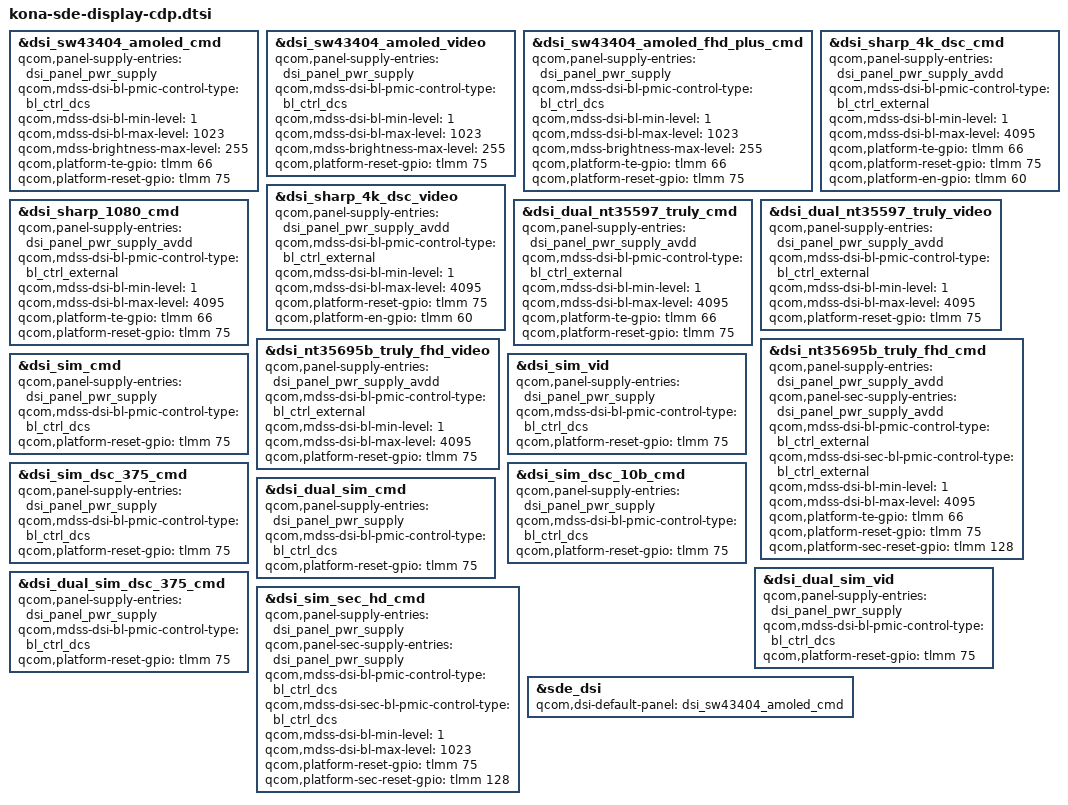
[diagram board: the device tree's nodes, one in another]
#include "kona-sde-display.dtsi"

&dsi_sw43404_amoled_cmd {
	qcom,panel-supply-entries = <&dsi_panel_pwr_supply>;
	qcom,mdss-dsi-bl-pmic-control-type = "bl_ctrl_dcs";
	qcom,mdss-dsi-bl-min-level = <1>;
	qcom,mdss-dsi-bl-max-level = <1023>;
	qcom,mdss-brightness-max-level = <255>;
	qcom,platform-te-gpio = <&tlmm 66 0>;
	qcom,platform-reset-gpio = <&tlmm 75 0>;
};

&dsi_sw43404_amoled_video {
	qcom,panel-supply-entries = <&dsi_panel_pwr_supply>;
	qcom,mdss-dsi-bl-pmic-control-type = "bl_ctrl_dcs";
	qcom,mdss-dsi-bl-min-level = <1>;
	qcom,mdss-dsi-bl-max-level = <1023>;
	qcom,mdss-brightness-max-level = <255>;
	qcom,platform-reset-gpio = <&tlmm 75 0>;
};

&dsi_sw43404_amoled_fhd_plus_cmd {
	qcom,panel-supply-entries = <&dsi_panel_pwr_supply>;
	qcom,mdss-dsi-bl-pmic-control-type = "bl_ctrl_dcs";
	qcom,mdss-dsi-bl-min-level = <1>;
	qcom,mdss-dsi-bl-max-level = <1023>;
	qcom,mdss-brightness-max-level = <255>;
	qcom,platform-te-gpio = <&tlmm 66 0>;
	qcom,platform-reset-gpio = <&tlmm 75 0>;
};

&dsi_sharp_4k_dsc_cmd {
	qcom,panel-supply-entries = <&dsi_panel_pwr_supply_avdd>;
	qcom,mdss-dsi-bl-pmic-control-type = "bl_ctrl_external";
	qcom,mdss-dsi-bl-min-level = <1>;
	qcom,mdss-dsi-bl-max-level = <4095>;
	qcom,platform-te-gpio = <&tlmm 66 0>;
	qcom,platform-reset-gpio = <&tlmm 75 0>;
	qcom,platform-en-gpio = <&tlmm 60 0>;
};

&dsi_sharp_4k_dsc_video {
	qcom,panel-supply-entries = <&dsi_panel_pwr_supply_avdd>;
	qcom,mdss-dsi-bl-pmic-control-type = "bl_ctrl_external";
	qcom,mdss-dsi-bl-min-level = <1>;
	qcom,mdss-dsi-bl-max-level = <4095>;
	qcom,platform-reset-gpio = <&tlmm 75 0>;
	qcom,platform-en-gpio = <&tlmm 60 0>;
};

&dsi_sharp_1080_cmd {
	qcom,panel-supply-entries = <&dsi_panel_pwr_supply_avdd>;
	qcom,mdss-dsi-bl-pmic-control-type = "bl_ctrl_external";
	qcom,mdss-dsi-bl-min-level = <1>;
	qcom,mdss-dsi-bl-max-level = <4095>;
	qcom,platform-te-gpio = <&tlmm 66 0>;
	qcom,platform-reset-gpio = <&tlmm 75 0>;
};

&dsi_dual_nt35597_truly_cmd {
	qcom,panel-supply-entries = <&dsi_panel_pwr_supply_avdd>;
	qcom,mdss-dsi-bl-pmic-control-type = "bl_ctrl_external";
	qcom,mdss-dsi-bl-min-level = <1>;
	qcom,mdss-dsi-bl-max-level = <4095>;
	qcom,platform-te-gpio = <&tlmm 66 0>;
	qcom,platform-reset-gpio = <&tlmm 75 0>;
};

&dsi_dual_nt35597_truly_video {
	qcom,panel-supply-entries = <&dsi_panel_pwr_supply_avdd>;
	qcom,mdss-dsi-bl-pmic-control-type = "bl_ctrl_external";
	qcom,mdss-dsi-bl-min-level = <1>;
	qcom,mdss-dsi-bl-max-level = <4095>;
	qcom,platform-reset-gpio = <&tlmm 75 0>;
};

&dsi_nt35695b_truly_fhd_cmd {
	qcom,panel-supply-entries = <&dsi_panel_pwr_supply_avdd>;
	qcom,panel-sec-supply-entries = <&dsi_panel_pwr_supply_avdd>;
	qcom,mdss-dsi-bl-pmic-control-type = "bl_ctrl_external";
	qcom,mdss-dsi-sec-bl-pmic-control-type = "bl_ctrl_external";
	qcom,mdss-dsi-bl-min-level = <1>;
	qcom,mdss-dsi-bl-max-level = <4095>;
	qcom,platform-te-gpio = <&tlmm 66 0>;
	qcom,platform-reset-gpio = <&tlmm 75 0>;
	qcom,platform-sec-reset-gpio = <&tlmm 128 0>;
};

&dsi_nt35695b_truly_fhd_video {
	qcom,panel-supply-entries = <&dsi_panel_pwr_supply_avdd>;
	qcom,mdss-dsi-bl-pmic-control-type = "bl_ctrl_external";
	qcom,mdss-dsi-bl-min-level = <1>;
	qcom,mdss-dsi-bl-max-level = <4095>;
	qcom,platform-reset-gpio = <&tlmm 75 0>;
};

&dsi_sim_cmd {
	qcom,panel-supply-entries = <&dsi_panel_pwr_supply>;
	qcom,mdss-dsi-bl-pmic-control-type = "bl_ctrl_dcs";
	qcom,platform-reset-gpio = <&tlmm 75 0>;
};

&dsi_sim_vid {
	qcom,panel-supply-entries = <&dsi_panel_pwr_supply>;
	qcom,mdss-dsi-bl-pmic-control-type = "bl_ctrl_dcs";
	qcom,platform-reset-gpio = <&tlmm 75 0>;
};

&dsi_sim_dsc_375_cmd {
	qcom,panel-supply-entries = <&dsi_panel_pwr_supply>;
	qcom,mdss-dsi-bl-pmic-control-type = "bl_ctrl_dcs";
	qcom,platform-reset-gpio = <&tlmm 75 0>;
};

&dsi_sim_dsc_10b_cmd {
	qcom,panel-supply-entries = <&dsi_panel_pwr_supply>;
	qcom,mdss-dsi-bl-pmic-control-type = "bl_ctrl_dcs";
	qcom,platform-reset-gpio = <&tlmm 75 0>;
};

&dsi_dual_sim_cmd {
	qcom,panel-supply-entries = <&dsi_panel_pwr_supply>;
	qcom,mdss-dsi-bl-pmic-control-type = "bl_ctrl_dcs";
	qcom,platform-reset-gpio = <&tlmm 75 0>;
};

&dsi_dual_sim_vid {
	qcom,panel-supply-entries = <&dsi_panel_pwr_supply>;
	qcom,mdss-dsi-bl-pmic-control-type = "bl_ctrl_dcs";
	qcom,platform-reset-gpio = <&tlmm 75 0>;
};

&dsi_dual_sim_dsc_375_cmd {
	qcom,panel-supply-entries = <&dsi_panel_pwr_supply>;
	qcom,mdss-dsi-bl-pmic-control-type = "bl_ctrl_dcs";
	qcom,platform-reset-gpio = <&tlmm 75 0>;
};

&dsi_sim_sec_hd_cmd {
	qcom,panel-supply-entries = <&dsi_panel_pwr_supply>;
	qcom,panel-sec-supply-entries = <&dsi_panel_pwr_supply>;
	qcom,mdss-dsi-bl-pmic-control-type = "bl_ctrl_dcs";
	qcom,mdss-dsi-sec-bl-pmic-control-type = "bl_ctrl_dcs";
	qcom,mdss-dsi-bl-min-level = <1>;
	qcom,mdss-dsi-bl-max-level = <1023>;
	qcom,platform-reset-gpio = <&tlmm 75 0>;
	qcom,platform-sec-reset-gpio = <&tlmm 128 0>;
};

&sde_dsi {
	qcom,dsi-default-panel = <&dsi_sw43404_amoled_cmd>;
};
